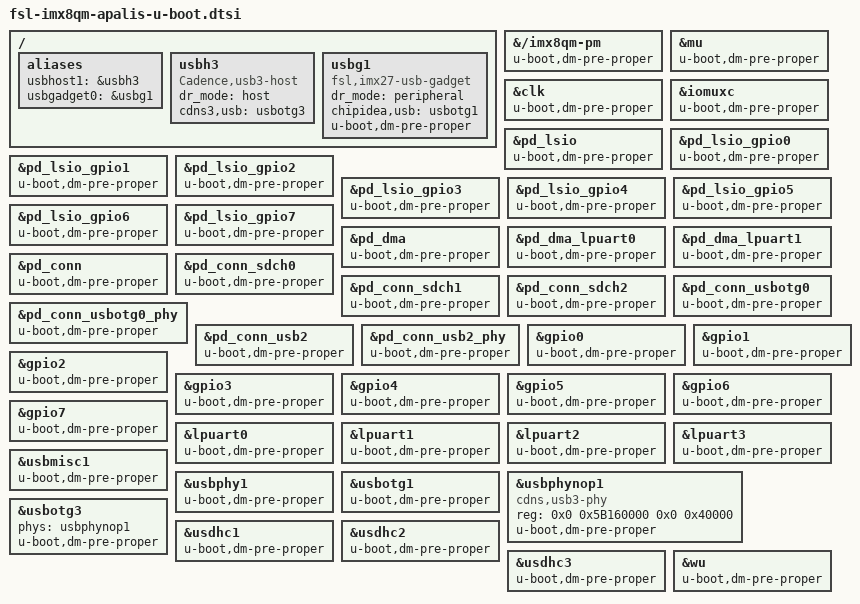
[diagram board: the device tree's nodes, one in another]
// SPDX-License-Identifier: GPL-2.0+ OR X11
/*
 * Copyright 2019 Toradex AG
 */
/ {
	aliases {
		usbhost1 = &usbh3;
		usbgadget0 = &usbg1;
	};

	usbh3: usbh3 {
		compatible = "Cadence,usb3-host";
		dr_mode = "host";
		cdns3,usb = <&usbotg3>;
		status = "okay";
	};

	usbg1: usbg1 {
		compatible = "fsl,imx27-usb-gadget";
		dr_mode = "peripheral";
		chipidea,usb = <&usbotg1>;
		status = "okay";
		u-boot,dm-pre-proper;
	};
};

&{/imx8qm-pm} {

	u-boot,dm-pre-proper;
};

&mu {
	u-boot,dm-pre-proper;
};

&clk {
	u-boot,dm-pre-proper;
};

&iomuxc {
	u-boot,dm-pre-proper;
};

&pd_lsio {
	u-boot,dm-pre-proper;
};

&pd_lsio_gpio0 {
	u-boot,dm-pre-proper;
};

&pd_lsio_gpio1 {
	u-boot,dm-pre-proper;
};

&pd_lsio_gpio2 {
	u-boot,dm-pre-proper;
};

&pd_lsio_gpio3 {
	u-boot,dm-pre-proper;
};

&pd_lsio_gpio4 {
	u-boot,dm-pre-proper;
};

&pd_lsio_gpio5 {
	u-boot,dm-pre-proper;
};

&pd_lsio_gpio6 {
	u-boot,dm-pre-proper;
};

&pd_lsio_gpio7 {
	u-boot,dm-pre-proper;
};

&pd_dma {
	u-boot,dm-pre-proper;
};

&pd_dma_lpuart0 {
	u-boot,dm-pre-proper;
};

&pd_dma_lpuart1 {
	u-boot,dm-pre-proper;
};

&pd_conn {
	u-boot,dm-pre-proper;
};

&pd_conn_sdch0 {
	u-boot,dm-pre-proper;
};

&pd_conn_sdch1 {
	u-boot,dm-pre-proper;
};

&pd_conn_sdch2 {
	u-boot,dm-pre-proper;
};

&pd_conn_usbotg0 {
	u-boot,dm-pre-proper;
};

&pd_conn_usbotg0_phy {
	u-boot,dm-pre-proper;
};

&pd_conn_usb2 {
	u-boot,dm-pre-proper;
};

&pd_conn_usb2_phy {
	u-boot,dm-pre-proper;
};

&gpio0 {
	u-boot,dm-pre-proper;
};

&gpio1 {
	u-boot,dm-pre-proper;
};

&gpio2 {
	u-boot,dm-pre-proper;
};

&gpio3 {
	u-boot,dm-pre-proper;
};

&gpio4 {
	u-boot,dm-pre-proper;
};

&gpio5 {
	u-boot,dm-pre-proper;
};

&gpio6 {
	u-boot,dm-pre-proper;
};

&gpio7 {
	u-boot,dm-pre-proper;
};

&lpuart0 {
	u-boot,dm-pre-proper;
};

&lpuart1 {
	u-boot,dm-pre-proper;
};

&lpuart2 {
	u-boot,dm-pre-proper;
};

&lpuart3 {
	u-boot,dm-pre-proper;
};

/* USB */
&usbmisc1 {
	u-boot,dm-pre-proper;
};

&usbphy1 {
	u-boot,dm-pre-proper;
};

&usbotg1 {
	u-boot,dm-pre-proper;
};

&usbphynop1 {
	compatible = "cdns,usb3-phy";
	reg = <0x0 0x5B160000 0x0 0x40000>;
	#phy-cells = <0>;
	u-boot,dm-pre-proper;
};

&usbotg3 {
	phys = <&usbphynop1>;
	u-boot,dm-pre-proper;
};

&usdhc1 {
	u-boot,dm-pre-proper;
};

&usdhc2 {
	u-boot,dm-pre-proper;
};

&usdhc3 {
	u-boot,dm-pre-proper;
};

&wu {
	u-boot,dm-pre-proper;
};
